# DSS_EDP0_V2A_CORE_VP_REGS_APB register map
Vendor: Texas Instruments
Registers are 32-bit, access not given, reset 0x0 unless marked. A register's access mark holds for its fields unless they carry their own. Offsets are as the file gives them; [hi:lo] are bit positions; lines under a group give offsets from that group; {n}, {i} and the like mark numbered series; 'fields as' and 'values as' point back to an identical list.

## DSS_EDP0_V2A_CORE_VP_REGS_APB (part 4 of 4)
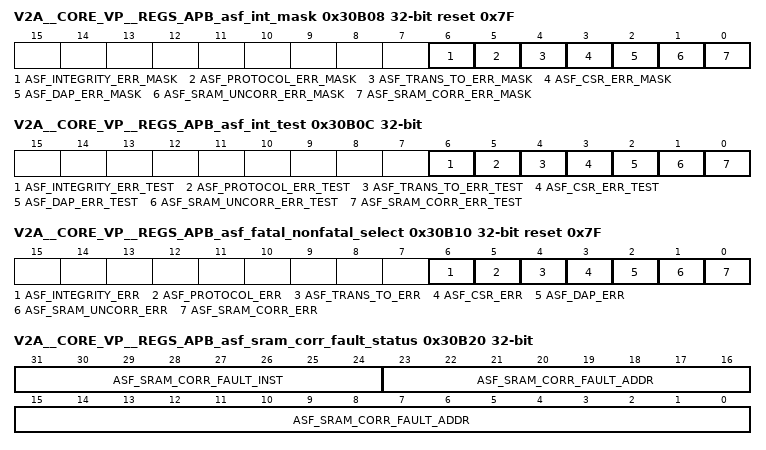
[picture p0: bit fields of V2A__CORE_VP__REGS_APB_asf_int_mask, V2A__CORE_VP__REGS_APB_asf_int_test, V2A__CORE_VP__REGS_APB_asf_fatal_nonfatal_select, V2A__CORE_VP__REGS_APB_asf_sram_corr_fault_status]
0x30B08 V2A__CORE_VP__REGS_APB_asf_int_mask reset 0x7F — The ASF interrupt mask register indicating which interrupt bits in the ASF interrupt status register are masked. All bits are set at reset. Clear the individual bit to enable the corresponding interrupt.
  [6] ASF_INTEGRITY_ERR_MASK rw — Mask bit for Integrity error interrupt, 0 is active, 1 is not active. Interrupt from source which mask is 0 is permitted, otherwise interrupt is not permitted
  [5] ASF_PROTOCOL_ERR_MASK rw — Mask bit for Protocol error interrupt, 0 is active, 1 is not active.Interrupt from source which mask is 0 is permitted, otherwise interrupt is not permitted
  [4] ASF_TRANS_TO_ERR_MASK rw — Mask bit for Transaction timeouts error interrupt, 0 is active, 1 is not active. Interrupt from source which mask is 0 is permitted, otherwise interrupt is not permitted
  [3] ASF_CSR_ERR_MASK rw — Mask bit for Configuration and status registers error interrupt, 0 is active, 1 is not active. Interrupt from source which mask is 0 is permitted, otherwise interrupt is not permitted
  [2] ASF_DAP_ERR_MASK rw — Mask bit for Data and address paths parity error interrupt, 0 is active, 1 is not active. Interrupt from source which mask is 0 is permitted, otherwise interrupt is not permitted
  [1] ASF_SRAM_UNCORR_ERR_MASK rw — Mask bit for SRAM uncorrectable error interrupt, 0 is active, 1 is not active. Interrupt from source which mask is 0 is permitted, otherwise interrupt is not permitted
  [0] ASF_SRAM_CORR_ERR_MASK rw — Mask bit for SRAM correctable error interrupt, 0 is active, 1 is not active. Interrupt from source which mask is 0 is permitted, otherwise interrupt is not permitted
0x30B0C V2A__CORE_VP__REGS_APB_asf_int_test — The ASF interrupt test register emulate hardware even. Write one to individual bit to trigger single event in (masked and raw) status registers according to mask and will generate interrupt accordingly.
  [6] ASF_INTEGRITY_ERR_TEST rw — Test bit for Integrity error interrupt,1 is active, 0 is not active
  [5] ASF_PROTOCOL_ERR_TEST rw — Test bit for Protocol error interrupt,1 is active, 0 is not active
  [4] ASF_TRANS_TO_ERR_TEST rw — Test bit for Transaction timeouts error interrupt,1 is active, 0 is not active
  [3] ASF_CSR_ERR_TEST rw — Test bit for Configuration and status registers error interrupt,1 is active, 0 is not active
  [2] ASF_DAP_ERR_TEST rw — Test bit for Data and address paths parity error interrupt,1 is active, 0 is not active
  [1] ASF_SRAM_UNCORR_ERR_TEST rw — Test bit for SRAM uncorrectable error interrupt,1 is active, 0 is not active
  [0] ASF_SRAM_CORR_ERR_TEST rw — Test bit for SRAM correctable error interrupt,1 is active, 0 is not active
0x30B10 V2A__CORE_VP__REGS_APB_asf_fatal_nonfatal_select reset 0x7F — The fatal or non-fatal interrupt register selects whether a fatal (asf_int_fatal) or non-fatal (asf_int_nonfatal) interrupt is triggered. If the bit of the event will be set to one then fatal interrupt (asf_int_fatal) will be triggered. Otherwise the non-fatal interrupt (asf_int_nonfatal) will be triggered.
  [6] ASF_INTEGRITY_ERR rw — Enable Integrity error interrupt as fatal,1 is fatal interrupt, 0 is non-fatal
  [5] ASF_PROTOCOL_ERR rw — Enable Protocol error interrupt as fatal,1 is fatal interrupt, 0 is non-fatal
  [4] ASF_TRANS_TO_ERR rw — Enable Transaction timeouts error interrupt as fatal,1 is fatal interrupt, 0 is non-fatal
  [3] ASF_CSR_ERR rw — Enable Configuration and status registers error interrupt as fatal,1 is fatal interrupt, 0 is non-fatal
  [2] ASF_DAP_ERR rw — Enable Data and address paths parity error interrupt as fatal,1 is fatal interrupt, 0 is non-fatal
  [1] ASF_SRAM_UNCORR_ERR rw — Enable SRAM uncorrectable error interrupt as fatal,1 is fatal interrupt, 0 is non-fatal
  [0] ASF_SRAM_CORR_ERR rw — Enable SRAM correctable error interrupt as fatal,1 is fatal interrupt, 0 is non-fatal
0x30B20 V2A__CORE_VP__REGS_APB_asf_sram_corr_fault_status ro — Status register for SRAM correctable fault. These fields are updated whenever asf_sram_corr_fault input is active.
  [31:24] ASF_SRAM_CORR_FAULT_INST — Last SRAM instance that generated fault
  [23:0] ASF_SRAM_CORR_FAULT_ADDR — Last SRAM address that generated fault
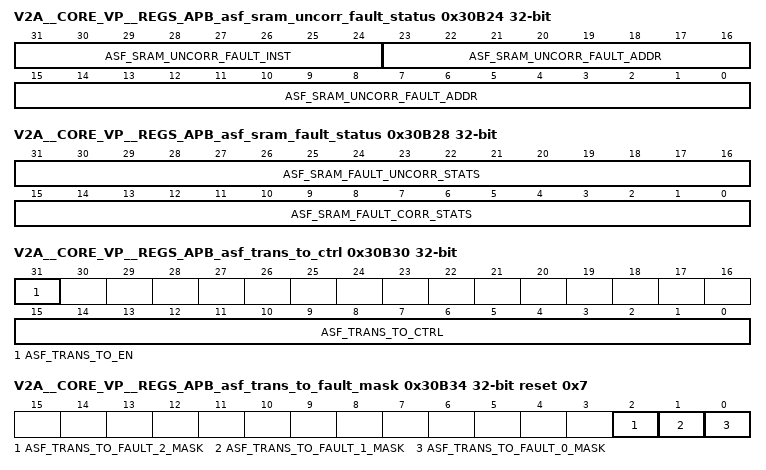
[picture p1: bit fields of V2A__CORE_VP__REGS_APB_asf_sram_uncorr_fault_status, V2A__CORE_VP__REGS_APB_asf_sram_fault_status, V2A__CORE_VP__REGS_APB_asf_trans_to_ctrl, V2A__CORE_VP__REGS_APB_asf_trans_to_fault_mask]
0x30B24 V2A__CORE_VP__REGS_APB_asf_sram_uncorr_fault_status ro — Status register for SRAM uncorrectable fault. These fields are updated whenever asf_sram_uncorr_fault input is active.
  [31:24] ASF_SRAM_UNCORR_FAULT_INST — Last SRAM instance that generated fault
  [23:0] ASF_SRAM_UNCORR_FAULT_ADDR — Last SRAM address that generated fault
0x30B28 V2A__CORE_VP__REGS_APB_asf_sram_fault_status rw — Statistics register for SRAM faults. Note that this register clears when software writes to any field.
  [31:16] ASF_SRAM_FAULT_UNCORR_STATS — Count of number of uncorrectable errors if implemented. Count value will saturate at 0xffff
  [15:0] ASF_SRAM_FAULT_CORR_STATS — Count of number of correctable errors if implemented. Count value will saturate at 0xffff
0x30B30 V2A__CORE_VP__REGS_APB_asf_trans_to_ctrl — Control register to configure the ASF transaction timeout monitors.
  [31] ASF_TRANS_TO_EN rw — Enable transaction timeout monitoring,1 is active,0 is not active
  [15:0] ASF_TRANS_TO_CTRL rw — Timer value to use for transaction timeout monitor
0x30B34 V2A__CORE_VP__REGS_APB_asf_trans_to_fault_mask reset 0x7 — Control register to mask out ASF transaction timeout faults from triggering interrupts. On reset, all bits are set to mask out all sources. Clear the corresponding bit to enable the interrupt source. The width of this field is parameterisable and the bit definitions are implementation specific.
  [2] ASF_TRANS_TO_FAULT_2_MASK rw — Mask bit for SAPB interface for transaction timeout fault,0 is active, 1 is not active.Interrupt from source which mask is 0 is permitted, otherwise interrupt is not permitted
  [1] ASF_TRANS_TO_FAULT_1_MASK rw — Mask bit for APB interface for transaction timeout fault,0 is active, 1 is not active.Interrupt from source which mask is 0 is permitted, otherwise interrupt is not permitted
  [0] ASF_TRANS_TO_FAULT_0_MASK rw — Mask bit for Xtensa watchdog error for transaction timeout fault,0 is active, 1 is not active.Interrupt from source which mask is 0 is permitted, otherwise interrupt is not permitted
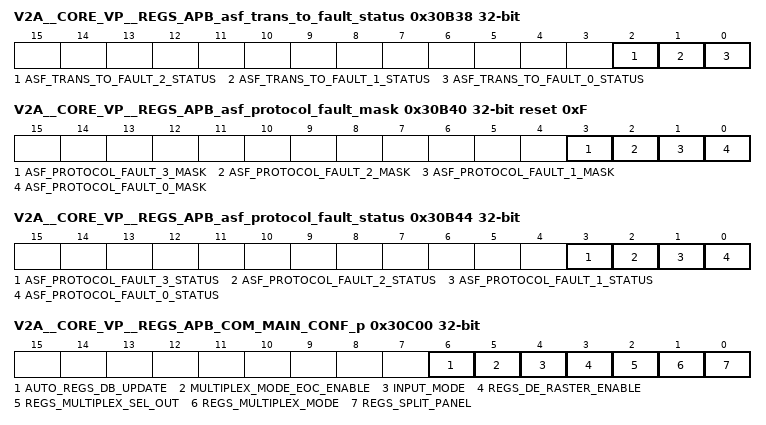
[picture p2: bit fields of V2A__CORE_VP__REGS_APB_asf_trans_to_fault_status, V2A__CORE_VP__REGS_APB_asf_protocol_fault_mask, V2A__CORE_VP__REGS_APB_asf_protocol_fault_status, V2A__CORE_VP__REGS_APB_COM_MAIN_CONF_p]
0x30B38 V2A__CORE_VP__REGS_APB_asf_trans_to_fault_status — Status register for transaction timeouts fault. If a fault occurs the revelant status bit will be set to 1. Each bit can be cleared by software writing 1 to each bit.
  [2] ASF_TRANS_TO_FAULT_2_STATUS rw — Status bits for SAPB interface for transaction timeout fault,1 is active, 0 is not active
  [1] ASF_TRANS_TO_FAULT_1_STATUS rw — Status bits for APB interface for transaction timeout fault,1 is active, 0 is not active
  [0] ASF_TRANS_TO_FAULT_0_STATUS rw — Status bits for Xtensa watchdog error for transaction timeout fault,1 is active, 0 is not active
0x30B40 V2A__CORE_VP__REGS_APB_asf_protocol_fault_mask reset 0xF — Control register to mask out ASF Protocol faults from triggering interrupts. On reset, all bits are set to mask out all sources. Clear the corresponding bit to enable the interrupt source. The width of this field is parameterisable and the bit definitions are implementation specific.
  [3] ASF_PROTOCOL_FAULT_3_MASK rw — Mask bit for FEC FSM fault. When 0 interrupt is enabled.
  [2] ASF_PROTOCOL_FAULT_2_MASK rw — Mask bit for 8b10b Encoding fault from FEC module. When 0 interrupt is enabled.
  [1] ASF_PROTOCOL_FAULT_1_MASK rw — Mask bit for Party Encoding fault from FEC module. When 0 interrupt is enabled.
  [0] ASF_PROTOCOL_FAULT_0_MASK rw — Mask bit for Parity Generation fault from FEC module. When 0 interrupt is enabled.
0x30B44 V2A__CORE_VP__REGS_APB_asf_protocol_fault_status — Status register for protocol faults. If a fault occurs the revelant status bit will be set to 1. Each bit can be cleared by software writing 1 to each bit
  [3] ASF_PROTOCOL_FAULT_3_STATUS rw — FEC symbol injection fault. Active HIGH. Asserten when FEC FSM is in unexpected state.
  [2] ASF_PROTOCOL_FAULT_2_STATUS rw — 8b10b Encoding fault in FEC module. Active HIGH. Asserted when fault in 8b10b encoding is detected.
  [1] ASF_PROTOCOL_FAULT_1_STATUS rw — Party Encoding fault in FEC module. Active HIGH. Asserted when fault in RS parity encoding is detected.
  [0] ASF_PROTOCOL_FAULT_0_STATUS rw — Parity Generation fault in FEC module. Active HIGH. Asserted when fault in RS parity generation is detected.
0x30C00 V2A__CORE_VP__REGS_APB_COM_MAIN_CONF_p — Encoder common configuration values
  [6] AUTO_REGS_DB_UPDATE rw — Active-High to enable auto update double buffer regs on vsync falling edge. Only available when input_mode=1 [DPI mode]
  [5] MULTIPLEX_MODE_EOC_ENABLE rw — When split_panel and multiplex_mode are set, indicates that multiplexer output separated chunks [inserts zeros on partial words at each end of chunk] and signal end of chunks. Active high
  [4] INPUT_MODE rw — Video input interface mode: 0: Native 1: DPI. Input mode set to DPI automatically enable the internal Auto Start Of Frame
  [3] REGS_DE_RASTER_ENABLE rw — Indicates if the De-Rasterization Buffer is used or bypassed: '1' Active '0' Bypassed
  [2] REGS_MULTIPLEX_SEL_OUT rw — When split_panel and multiplex_mode are set, indicates to which output the multiplexed stream is sent: '0': enc0_data_out '1': enc1_data_out
  [1] REGS_MULTIPLEX_MODE rw — Active-High, indicates that both encoders are used to produce a multiplex stream on a single Transport link. When set, split_panel must also be set.
  [0] REGS_SPLIT_PANEL rw — Active-High, indicates that both encoders are used in parallel for one video stream [L and R split]. When set, the effective width of each encoder is halved [as each encoder is operating on half of the encx_picture_width]. In addition, the ICH is cleared at the end of each line.
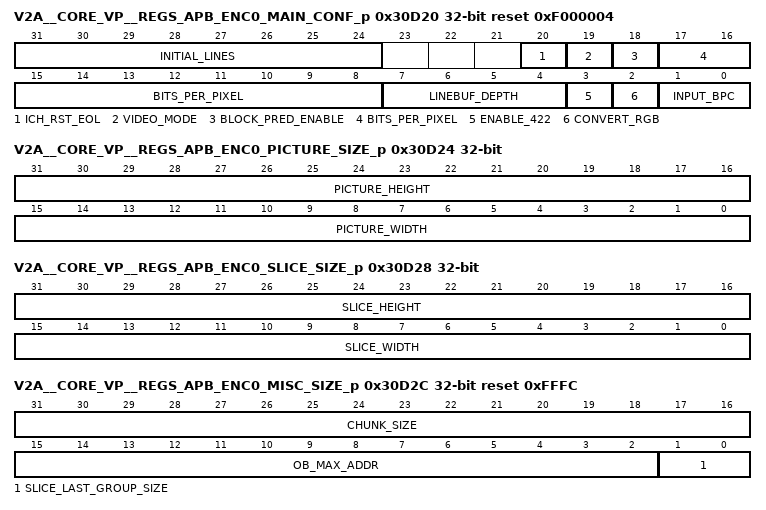
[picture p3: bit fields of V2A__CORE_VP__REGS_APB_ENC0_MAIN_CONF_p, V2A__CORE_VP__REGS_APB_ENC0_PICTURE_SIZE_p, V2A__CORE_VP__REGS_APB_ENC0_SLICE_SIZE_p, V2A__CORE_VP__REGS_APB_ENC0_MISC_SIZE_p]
0x30D20 V2A__CORE_VP__REGS_APB_ENC0_MAIN_CONF_p reset 0xF000004 — Encoder Main Configuration values
  [31:24] INITIAL_LINES rw — Number of lines to wait before initiating transport in Command Mode.
  [20] ICH_RST_EOL rw — Forces the ICH to reset at EOL [when not in split mode].
  [19] VIDEO_MODE rw — MIPI Video/Command mode: '0' Command mode '1' Video mode
  [18] BLOCK_PRED_ENABLE rw — Active-High input Block Prediction Enable
  [17:8] BITS_PER_PIXEL rw — Target bits per pixel. The value is in 6.4 format [4 LSBs for fractional part, they should be 0000]
  [7:4] LINEBUF_DEPTH rw — Depth of the line buffer used by the decoder [i.e., the number of bits stored for each component of the pixels on the previous line]
  [3] ENABLE_422 rw — Active-High input to indicate the data_in pixels are 4:2:2 sub-sampled. This input is valid only when convert_rgb is low. NOT SUPPORTED, MUST BE SET TO '0'
  [2] CONVERT_RGB rw — Active-High input to indicate the data_in pixels are RGB. When set to low input, it is YUV and does not require conversion.
  [1:0] INPUT_BPC rw — Indicates the current input pixel stream bits per component: 00: input is 8 bits/component 01: input is 10 bits/component
0x30D24 V2A__CORE_VP__REGS_APB_ENC0_PICTURE_SIZE_p rw — Encoder Picture configuration
  [31:16] PICTURE_HEIGHT, [15:0] PICTURE_WIDTH
0x30D28 V2A__CORE_VP__REGS_APB_ENC0_SLICE_SIZE_p rw — Encoder Slice(s) configuration
  [31:16] SLICE_HEIGHT, [15:0] SLICE_WIDTH
0x30D2C V2A__CORE_VP__REGS_APB_ENC0_MISC_SIZE_p rw reset 0xFFFC — Encoder Group, Output Buffer(s), and Transport Chunk Size
  [31:16] CHUNK_SIZE — Chunk size in bytes
  [15:2] OB_MAX_ADDR — Output Buffer[s] max pointer address[es]
  [1:0] SLICE_LAST_GROUP_SIZE — Size of last group of the slice line [0-based]: 0 = 1 pixel, 1 = 2 pixels, 2 = 3 pixels [slice_width + 2] % 3
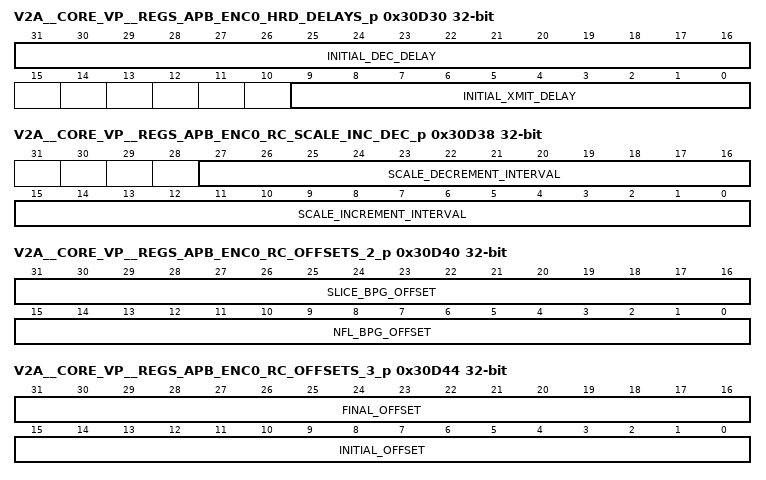
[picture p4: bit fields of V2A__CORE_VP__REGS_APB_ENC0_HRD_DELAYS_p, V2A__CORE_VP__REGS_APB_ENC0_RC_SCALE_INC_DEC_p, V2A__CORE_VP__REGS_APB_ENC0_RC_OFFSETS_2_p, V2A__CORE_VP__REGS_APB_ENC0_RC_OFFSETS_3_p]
0x30D30 V2A__CORE_VP__REGS_APB_ENC0_HRD_DELAYS_p — Hypothetical Reference Decoder delays
  [31:16] INITIAL_DEC_DELAY rw — Initial Decoder delay
  [9:0] INITIAL_XMIT_DELAY rw — Initial Decoder Transmit delay
0x30D34 V2A__CORE_VP__REGS_APB_ENC0_RC_SCALE_p — RC Calculate Buffer Fullness and Offset, Scale value
  [5:0] INITIAL_SCALE_VALUE rw — Three fractional bits
0x30D38 V2A__CORE_VP__REGS_APB_ENC0_RC_SCALE_INC_DEC_p — RC Calculate Buffer Fullness and Offset, Increment and Decrement Scale values
  [27:16] SCALE_DECREMENT_INTERVAL rw — RC scale decrement value
  [15:0] SCALE_INCREMENT_INTERVAL rw — RC scale increment value
0x30D3C V2A__CORE_VP__REGS_APB_ENC0_RC_OFFSETS_1_p — RC Calculate Buffer Fullness and Offset, Various Offset control values 1
  [4:0] FIRST_LINE_BPG_OFFSET rw — First Line
0x30D40 V2A__CORE_VP__REGS_APB_ENC0_RC_OFFSETS_2_p rw — RC Calculate Buffer Fullness and Offset, Various Offset control values 2
  [31:16] SLICE_BPG_OFFSET — Extra budget per group [11 fractional bits]
  [15:0] NFL_BPG_OFFSET — Non First Line [11 fractional bits]
0x30D44 V2A__CORE_VP__REGS_APB_ENC0_RC_OFFSETS_3_p rw — RC Calculate Buffer Fullness and Offset, Various Offset control values 3
  [31:16] FINAL_OFFSET, [15:0] INITIAL_OFFSET
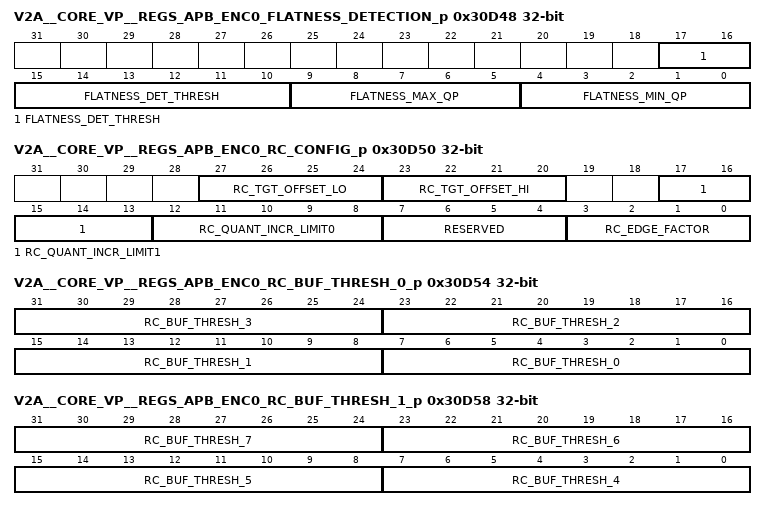
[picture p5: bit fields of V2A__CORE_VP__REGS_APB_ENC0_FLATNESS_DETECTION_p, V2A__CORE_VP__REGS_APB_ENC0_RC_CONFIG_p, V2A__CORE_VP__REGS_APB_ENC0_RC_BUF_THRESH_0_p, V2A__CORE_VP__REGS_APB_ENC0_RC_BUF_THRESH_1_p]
0x30D48 V2A__CORE_VP__REGS_APB_ENC0_FLATNESS_DETECTION_p — Flatness Signaling QP Override thresholds
  [17:10] FLATNESS_DET_THRESH rw — Flatness Detection Threshold, as defined in PPS table of the DSC specification
  [9:5] FLATNESS_MAX_QP rw — Maximum threshold
  [4:0] FLATNESS_MIN_QP rw — Minimum threshold
0x30D4C V2A__CORE_VP__REGS_APB_ENC0_RC_MODEL_SIZE_p — RC Model Size
  [15:0] RC_MODEL_SIZE rw
0x30D50 V2A__CORE_VP__REGS_APB_ENC0_RC_CONFIG_p — RC Model Various Config
  [27:24] RC_TGT_OFFSET_LO rw — RC Target offset low
  [23:20] RC_TGT_OFFSET_HI rw — RC Target offset high
  [17:13] RC_QUANT_INCR_LIMIT1 rw — RC quantization increment limit 1
  [12:8] RC_QUANT_INCR_LIMIT0 rw — RC quantization increment limit 0
  [7:4] RESERVED — RC Edge factor [1 fractional bit] (access N/A)
  [3:0] RC_EDGE_FACTOR rw — Reserved. Writes are ignored. 0x0 when read
0x30D54 V2A__CORE_VP__REGS_APB_ENC0_RC_BUF_THRESH_0_p rw — RC Model Buffer Thresholds 0
  [8n+7:8n] RC_BUF_THRESH_{n} (n=0..3) — 8 MSBs of the value. Values in configuration files are 14 bits but 6 LSBs are always 0
0x30D58 V2A__CORE_VP__REGS_APB_ENC0_RC_BUF_THRESH_1_p rw — RC Model Buffer Thresholds 1
  [8n-25:8n-32] RC_BUF_THRESH_{n} (n=4..7) — 8 MSBs of the value. Values in configuration files are 14 bits but 6 LSBs are always 0
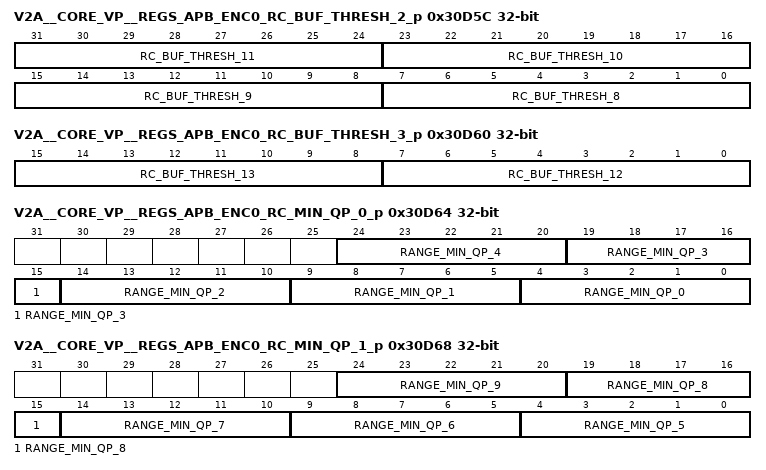
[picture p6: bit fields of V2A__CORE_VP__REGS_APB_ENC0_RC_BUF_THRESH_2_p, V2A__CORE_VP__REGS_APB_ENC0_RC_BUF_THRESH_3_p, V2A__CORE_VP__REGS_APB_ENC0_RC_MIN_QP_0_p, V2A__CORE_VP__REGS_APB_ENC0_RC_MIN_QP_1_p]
0x30D5C V2A__CORE_VP__REGS_APB_ENC0_RC_BUF_THRESH_2_p rw — RC Model Buffer Thresholds 2
  [8n-57:8n-64] RC_BUF_THRESH_{n} (n=8..11) — 8 MSBs of the value. Values in configuration files are 14 bits but 6 LSBs are always 0
0x30D60 V2A__CORE_VP__REGS_APB_ENC0_RC_BUF_THRESH_3_p — RC Model Buffer Thresholds 3
  [15:8] RC_BUF_THRESH_13 rw — 8 MSBs of the value. Values in configuration files are 14 bits but 6 LSBs are always 0
  [7:0] RC_BUF_THRESH_12 rw — 8 MSBs of the value. Values in configuration files are 14 bits but 6 LSBs are always 0
0x30D64 V2A__CORE_VP__REGS_APB_ENC0_RC_MIN_QP_0_p — RC Min QP 0
  [5n+4:5n] RANGE_MIN_QP_{n} rw (n=0..4) — As per DSC specification
0x30D68 V2A__CORE_VP__REGS_APB_ENC0_RC_MIN_QP_1_p — RC Min QP 1
  [5n-21:5n-25] RANGE_MIN_QP_{n} rw (n=5..9) — As per DSC specification
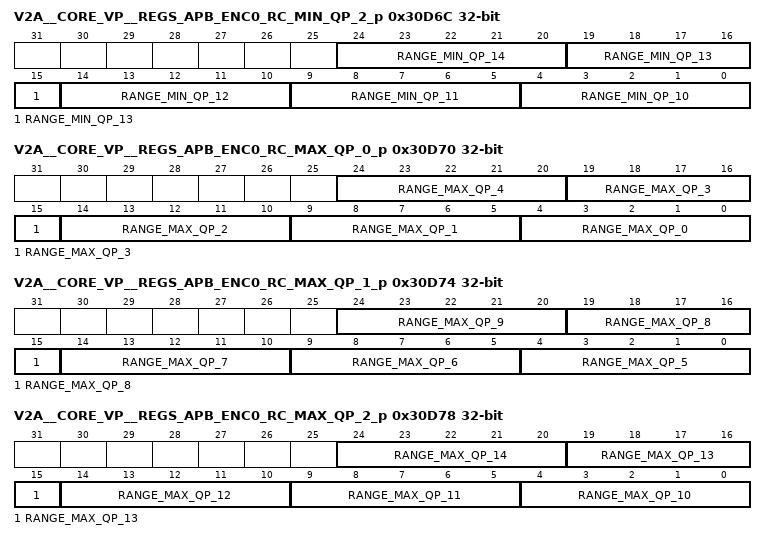
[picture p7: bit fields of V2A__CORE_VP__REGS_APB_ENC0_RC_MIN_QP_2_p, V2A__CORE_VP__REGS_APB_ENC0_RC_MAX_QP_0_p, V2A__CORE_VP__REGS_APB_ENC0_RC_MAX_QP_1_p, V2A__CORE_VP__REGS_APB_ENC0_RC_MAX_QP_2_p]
0x30D6C V2A__CORE_VP__REGS_APB_ENC0_RC_MIN_QP_2_p — RC Min QP 2
  [5n-46:5n-50] RANGE_MIN_QP_{n} rw (n=10..14) — As per DSC specification
0x30D70 V2A__CORE_VP__REGS_APB_ENC0_RC_MAX_QP_0_p — RC Max QP 0
  [5n+4:5n] RANGE_MAX_QP_{n} rw (n=0..4) — As per DSC specification
0x30D74 V2A__CORE_VP__REGS_APB_ENC0_RC_MAX_QP_1_p — RC Max QP 1
  [5n-21:5n-25] RANGE_MAX_QP_{n} rw (n=5..9) — As per DSC specification
0x30D78 V2A__CORE_VP__REGS_APB_ENC0_RC_MAX_QP_2_p — RC Max QP 2
  [5n-46:5n-50] RANGE_MAX_QP_{n} rw (n=10..14) — As per DSC specification
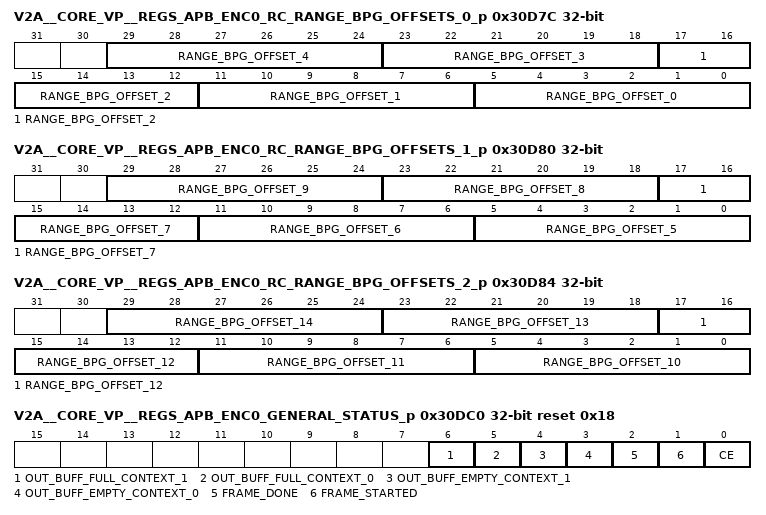
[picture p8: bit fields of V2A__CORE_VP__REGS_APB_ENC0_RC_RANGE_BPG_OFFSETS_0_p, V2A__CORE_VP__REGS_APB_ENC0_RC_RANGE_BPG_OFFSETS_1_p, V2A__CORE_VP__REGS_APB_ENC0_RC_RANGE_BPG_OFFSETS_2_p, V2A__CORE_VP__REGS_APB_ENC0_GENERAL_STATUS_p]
0x30D7C V2A__CORE_VP__REGS_APB_ENC0_RC_RANGE_BPG_OFFSETS_0_p — RC Range bpg Offsets 0
  [6n+5:6n] RANGE_BPG_OFFSET_{n} rw (n=0..4) — As per DSC specification
0x30D80 V2A__CORE_VP__REGS_APB_ENC0_RC_RANGE_BPG_OFFSETS_1_p — RC Range bpg Offsets 1
  [6n-25:6n-30] RANGE_BPG_OFFSET_{n} rw (n=5..9) — As per DSC specification
0x30D84 V2A__CORE_VP__REGS_APB_ENC0_RC_RANGE_BPG_OFFSETS_2_p — RC Range bpg Offsets 2
  [6n-55:6n-60] RANGE_BPG_OFFSET_{n} rw (n=10..14) — As per DSC specification
0x30D88 V2A__CORE_VP__REGS_APB_ENC0_DPI_CTRL_OUT_DELAY_p — Delay applied to DPI input control signals to generate DPI output control signals
  [15:0] DPI_CTRL_OUT_DELAY rw — Delay in number of encx clock cycles. The delay should equal to InitialLines x Htotal[clk] where Htotal is the upstream source timing controller total line time [in clock cycles, not in pixels] including the horizontal blanking [Htotal[clk] = Hactive[clk] + Hblank[clk]]When in split panel mode, the Hactive[clk] is expected to be picture_width divided by 2
0x30DC0 V2A__CORE_VP__REGS_APB_ENC0_GENERAL_STATUS_p reset 0x18 — General Encoder Status
  [6] OUT_BUFF_FULL_CONTEXT_1 ro — Output buffer 1 [soft slice 1] is full.For Debug purposes only.
  [5] OUT_BUFF_FULL_CONTEXT_0 ro — Output buffer 0 [soft slice 0] is full.For Debug purposes only.
  [4] OUT_BUFF_EMPTY_CONTEXT_1 ro — Output buffer 1 [soft slice 1] is empty.For Debug purposes only.
  [3] OUT_BUFF_EMPTY_CONTEXT_0 ro — Output buffer 0 [soft slice 0] is empty.For Debug purposes only.
  [2] FRAME_DONE ro — Encoder finished a frame
  [1] FRAME_STARTED ro — Encoder is currently processing a frame
  [0] CE ro — Flow control internal clock enable status.For Debug purposes only.
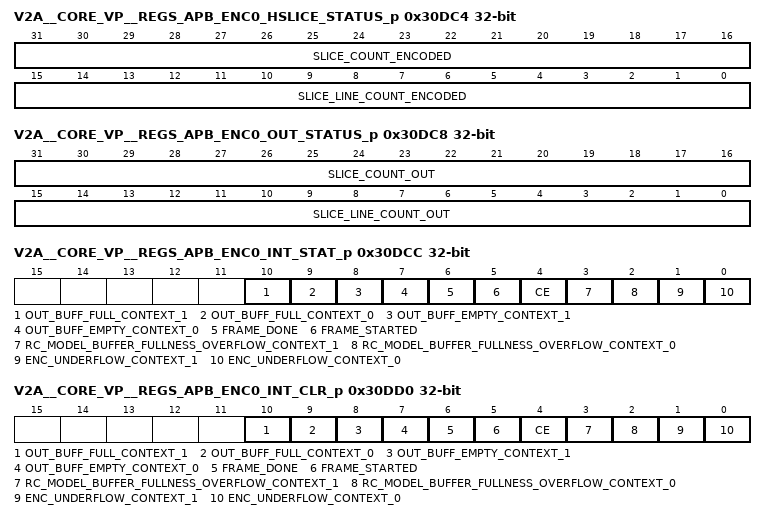
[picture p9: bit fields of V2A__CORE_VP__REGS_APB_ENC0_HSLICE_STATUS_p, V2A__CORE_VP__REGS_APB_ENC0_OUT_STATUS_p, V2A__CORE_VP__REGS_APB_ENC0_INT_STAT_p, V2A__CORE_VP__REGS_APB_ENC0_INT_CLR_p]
0x30DC4 V2A__CORE_VP__REGS_APB_ENC0_HSLICE_STATUS_p ro — Hard Slice Encoded Status
  [31:16] SLICE_COUNT_ENCODED — Actual slice number of current frame being processed at VLC encoder.Not re-synchronized in register clock domain. For Debug purposes only.
  [15:0] SLICE_LINE_COUNT_ENCODED — Actual line number of current slice being processed at VLC encoder.Not re-synchronized in register clock domain. For Debug purposes only.
0x30DC8 V2A__CORE_VP__REGS_APB_ENC0_OUT_STATUS_p ro — Outputted Slice Status
  [31:16] SLICE_COUNT_OUT — Actual slice number of current frame being read at output interface.Not re-synchronized in register clock domain. For Debug purposes only.
  [15:0] SLICE_LINE_COUNT_OUT — Actual line number of current slice being read at output interface.Not re-synchronized in register clock domain. For Debug purposes only.
0x30DCC V2A__CORE_VP__REGS_APB_ENC0_INT_STAT_p — Encoder Interrupt Status
  [10] OUT_BUFF_FULL_CONTEXT_1 ro — Output buffer 1 [soft slice 1] became full
  [9] OUT_BUFF_FULL_CONTEXT_0 ro — Output buffer 0 [soft slice 0] became full
  [8] OUT_BUFF_EMPTY_CONTEXT_1 ro — Output buffer 1 [soft slice 1] became empty
  [7] OUT_BUFF_EMPTY_CONTEXT_0 ro — Output buffer 0 [soft slice 0] became empty
  [6] FRAME_DONE ro — Encoder finished a frame
  [5] FRAME_STARTED ro — Encoder is started to process a frame
  [4] CE ro — Flow control internal clock enable becomes high
  [3] RC_MODEL_BUFFER_FULLNESS_OVERFLOW_CONTEXT_1 ro — rc_model_buffer 1 [soft slice 1] overflow
  [2] RC_MODEL_BUFFER_FULLNESS_OVERFLOW_CONTEXT_0 ro — rc_model_buffer 0 [soft slice 0] overflow
  [1] ENC_UNDERFLOW_CONTEXT_1 ro — output buffer 1 [soft slice 1] underflow
  [0] ENC_UNDERFLOW_CONTEXT_0 ro — output buffer 0 [soft slice 0] underflow
0x30DD0 V2A__CORE_VP__REGS_APB_ENC0_INT_CLR_p — Encoder Interrupt Clear. Setting any one of these bits, clears the corresponding ENC_INT_STAT bits. This register is self-clearing after 8 regs_pclk cycles.
  [10] OUT_BUFF_FULL_CONTEXT_1 rw — Output buffer 1 [soft slice 1] became full
  [9] OUT_BUFF_FULL_CONTEXT_0 rw — Output buffer 0 [soft slice 0] became full
  [8] OUT_BUFF_EMPTY_CONTEXT_1 rw — Output buffer 1 [soft slice 1] became empty
  [7] OUT_BUFF_EMPTY_CONTEXT_0 rw — Output buffer 0 [soft slice 0] became empty
  [6] FRAME_DONE rw — Encoder finished a frame
  [5] FRAME_STARTED rw — Encoder is started to process a frame
  [4] CE rw — Flow control internal clock enable
  [3] RC_MODEL_BUFFER_FULLNESS_OVERFLOW_CONTEXT_1 rw — rc model buffer 1 overflow
  [2] RC_MODEL_BUFFER_FULLNESS_OVERFLOW_CONTEXT_0 rw — rc model buffer 0 overflow
  [1] ENC_UNDERFLOW_CONTEXT_1 rw — output buffer 1 underflow
  [0] ENC_UNDERFLOW_CONTEXT_0 rw — output buffer 0 underflow
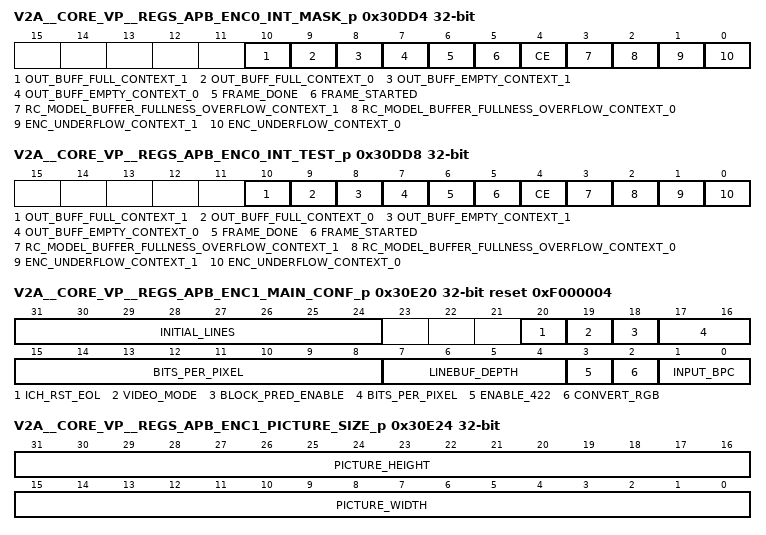
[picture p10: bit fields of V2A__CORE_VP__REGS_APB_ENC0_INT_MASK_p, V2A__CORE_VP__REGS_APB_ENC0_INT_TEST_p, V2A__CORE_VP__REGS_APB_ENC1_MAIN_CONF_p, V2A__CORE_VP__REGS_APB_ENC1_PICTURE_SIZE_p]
0x30DD4 V2A__CORE_VP__REGS_APB_ENC0_INT_MASK_p — Encoder Interrupt Mask. Any bit set to 1'b1 is enabled to report an interrupt on the corresponding bit position
  [10] OUT_BUFF_FULL_CONTEXT_1 rw — Output buffer 1 [soft slice 1] became full
  [9] OUT_BUFF_FULL_CONTEXT_0 rw — Output buffer 0 [soft slice 0] became full
  [8] OUT_BUFF_EMPTY_CONTEXT_1 rw — Output buffer 1 [soft slice 1] became empty
  [7] OUT_BUFF_EMPTY_CONTEXT_0 rw — Output buffer 0 [soft slice 0] became empty
  [6] FRAME_DONE rw — Encoder finished a frame
  [5] FRAME_STARTED rw — Encoder is started to process a frame
  [4] CE rw — Flow control internal clock enable
  [3] RC_MODEL_BUFFER_FULLNESS_OVERFLOW_CONTEXT_1 rw — rc model buffer 1 overflow
  [2] RC_MODEL_BUFFER_FULLNESS_OVERFLOW_CONTEXT_0 rw — rc model buffer 0 overflow
  [1] ENC_UNDERFLOW_CONTEXT_1 rw — enc underflow 1 underflow
  [0] ENC_UNDERFLOW_CONTEXT_0 rw — enc underflow 0 underflow
0x30DD8 V2A__CORE_VP__REGS_APB_ENC0_INT_TEST_p — Encoder Interrupt Test. Setting any one of these bits to 0x0 and then to 0x1 simulate a hardware event and generate an interrupt if the corresponding ENCx_INT_MASK bit is set.
  [10] OUT_BUFF_FULL_CONTEXT_1 rw — Output buffer 1 [soft slice 1] became full test
  [9] OUT_BUFF_FULL_CONTEXT_0 rw — Output buffer 0 [soft slice 0] became full test
  [8] OUT_BUFF_EMPTY_CONTEXT_1 rw — Output buffer 1 [soft slice 1] became empty test
  [7] OUT_BUFF_EMPTY_CONTEXT_0 rw — Output buffer 0 [soft slice 0] became empty test
  [6] FRAME_DONE rw — Encoder finished a frame test
  [5] FRAME_STARTED rw — Encoder is started to process a frame test
  [4] CE rw — Flow control internal clock enable test
  [3] RC_MODEL_BUFFER_FULLNESS_OVERFLOW_CONTEXT_1 rw — rc model buffer 1 overflow test
  [2] RC_MODEL_BUFFER_FULLNESS_OVERFLOW_CONTEXT_0 rw — rc model buffer 0 overflow test
  [1] ENC_UNDERFLOW_CONTEXT_1 rw — enc underflow 1 underflow test
  [0] ENC_UNDERFLOW_CONTEXT_0 rw — enc underflow 0 underflow test
0x30E20 V2A__CORE_VP__REGS_APB_ENC1_MAIN_CONF_p reset 0xF000004 — Encoder Main Configuration values test
  fields as V2A__CORE_VP__REGS_APB_ENC0_MAIN_CONF_p
0x30E24 V2A__CORE_VP__REGS_APB_ENC1_PICTURE_SIZE_p rw — Encoder Picture configuration
  [31:16] PICTURE_HEIGHT, [15:0] PICTURE_WIDTH
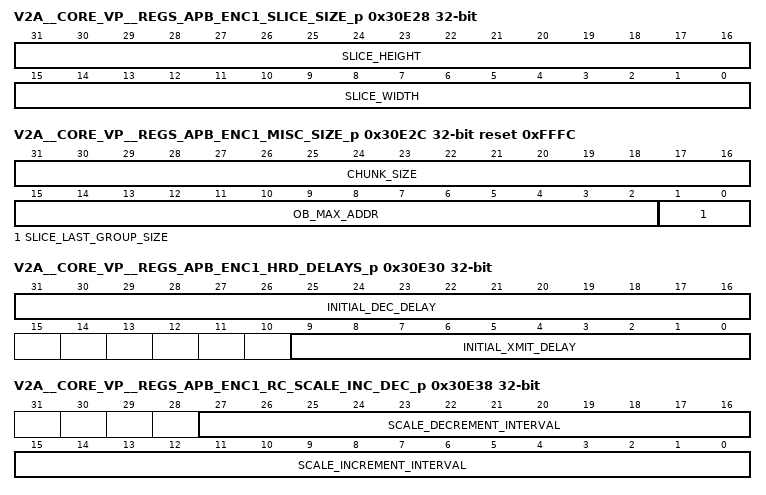
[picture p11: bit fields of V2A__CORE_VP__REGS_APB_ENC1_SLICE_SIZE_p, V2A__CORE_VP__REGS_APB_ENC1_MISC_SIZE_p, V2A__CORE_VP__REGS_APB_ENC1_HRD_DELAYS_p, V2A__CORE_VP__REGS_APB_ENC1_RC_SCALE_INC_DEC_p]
0x30E28 V2A__CORE_VP__REGS_APB_ENC1_SLICE_SIZE_p rw — Encoder Slice(s) configuration
  [31:16] SLICE_HEIGHT, [15:0] SLICE_WIDTH
0x30E2C V2A__CORE_VP__REGS_APB_ENC1_MISC_SIZE_p rw reset 0xFFFC — Encoder Group, Output Buffer(s), and Transport Chunk Size
  fields as V2A__CORE_VP__REGS_APB_ENC0_MISC_SIZE_p
0x30E30 V2A__CORE_VP__REGS_APB_ENC1_HRD_DELAYS_p — Hypothetical Reference Decoder delays
  fields as V2A__CORE_VP__REGS_APB_ENC0_HRD_DELAYS_p
0x30E34 V2A__CORE_VP__REGS_APB_ENC1_RC_SCALE_p — RC Calculate Buffer Fullness and Offset, Scale value
  [5:0] INITIAL_SCALE_VALUE rw — Three fractional bits
0x30E38 V2A__CORE_VP__REGS_APB_ENC1_RC_SCALE_INC_DEC_p — RC Calculate Buffer Fullness and Offset, Increment and Decrement Scale values
  fields as V2A__CORE_VP__REGS_APB_ENC0_RC_SCALE_INC_DEC_p
0x30E3C V2A__CORE_VP__REGS_APB_ENC1_RC_OFFSETS_1_p — RC Calculate Buffer Fullness and Offset, Various Offset control values 1
  [4:0] FIRST_LINE_BPG_OFFSET rw — First Line
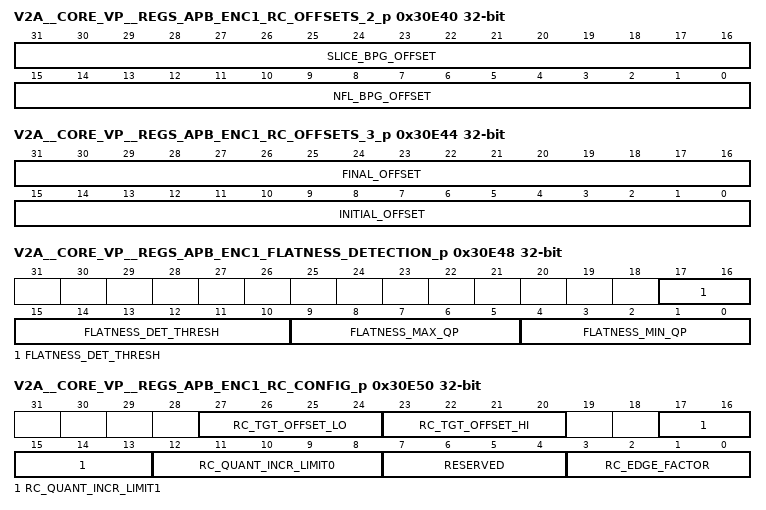
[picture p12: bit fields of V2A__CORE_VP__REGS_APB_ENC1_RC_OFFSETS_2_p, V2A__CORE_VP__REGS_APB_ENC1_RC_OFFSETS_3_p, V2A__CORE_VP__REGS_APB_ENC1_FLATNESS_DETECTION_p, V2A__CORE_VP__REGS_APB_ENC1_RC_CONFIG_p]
0x30E40 V2A__CORE_VP__REGS_APB_ENC1_RC_OFFSETS_2_p rw — RC Calculate Buffer Fullness and Offset, Various Offset control values 2
  fields as V2A__CORE_VP__REGS_APB_ENC0_RC_OFFSETS_2_p
0x30E44 V2A__CORE_VP__REGS_APB_ENC1_RC_OFFSETS_3_p rw — RC Calculate Buffer Fullness and Offset, Various Offset control values 3
  [31:16] FINAL_OFFSET, [15:0] INITIAL_OFFSET
0x30E48 V2A__CORE_VP__REGS_APB_ENC1_FLATNESS_DETECTION_p — Flatness Signaling QP Override thresholds
  fields as V2A__CORE_VP__REGS_APB_ENC0_FLATNESS_DETECTION_p
0x30E4C V2A__CORE_VP__REGS_APB_ENC1_RC_MODEL_SIZE_p — RC Model Size
  [15:0] RC_MODEL_SIZE rw
0x30E50 V2A__CORE_VP__REGS_APB_ENC1_RC_CONFIG_p — RC Model Various Config
  fields as V2A__CORE_VP__REGS_APB_ENC0_RC_CONFIG_p
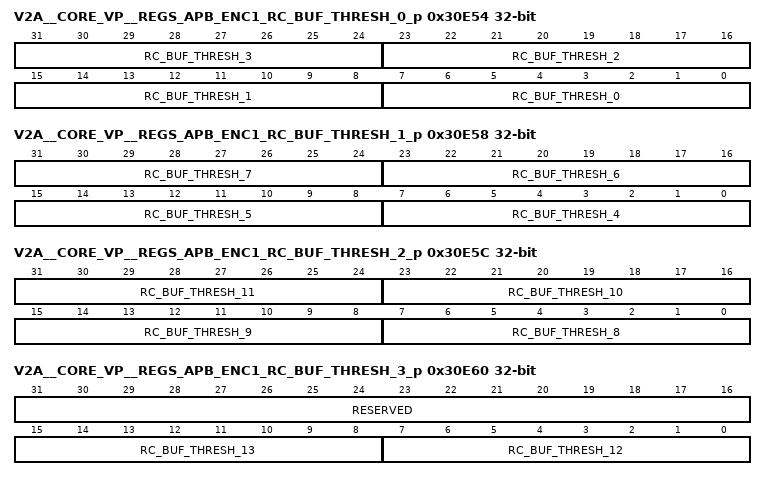
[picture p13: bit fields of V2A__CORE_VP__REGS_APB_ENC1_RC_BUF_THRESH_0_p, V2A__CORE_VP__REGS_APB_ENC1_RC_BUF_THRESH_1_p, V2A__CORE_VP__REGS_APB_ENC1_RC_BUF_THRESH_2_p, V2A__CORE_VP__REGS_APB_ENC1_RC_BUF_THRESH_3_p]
0x30E54 V2A__CORE_VP__REGS_APB_ENC1_RC_BUF_THRESH_0_p rw — RC Model Buffer Thresholds 0
  fields as V2A__CORE_VP__REGS_APB_ENC0_RC_BUF_THRESH_0_p
0x30E58 V2A__CORE_VP__REGS_APB_ENC1_RC_BUF_THRESH_1_p rw — RC Model Buffer Thresholds 1
  fields as V2A__CORE_VP__REGS_APB_ENC0_RC_BUF_THRESH_1_p
0x30E5C V2A__CORE_VP__REGS_APB_ENC1_RC_BUF_THRESH_2_p rw — RC Model Buffer Thresholds 2
  fields as V2A__CORE_VP__REGS_APB_ENC0_RC_BUF_THRESH_2_p
0x30E60 V2A__CORE_VP__REGS_APB_ENC1_RC_BUF_THRESH_3_p — RC Model Buffer Thresholds 3
  [31:16] RESERVED — 8 MSBs of the value. Values in configuration files are 14 bits but 6 LSBs are always 0 (access N/A)
  [15:8] RC_BUF_THRESH_13 rw — 8 MSBs of the value. Values in configuration files are 14 bits but 6 LSBs are always 0
  [7:0] RC_BUF_THRESH_12 rw — 8 MSBs of the value. Values in configuration files are 14 bits but 6 LSBs are always 0
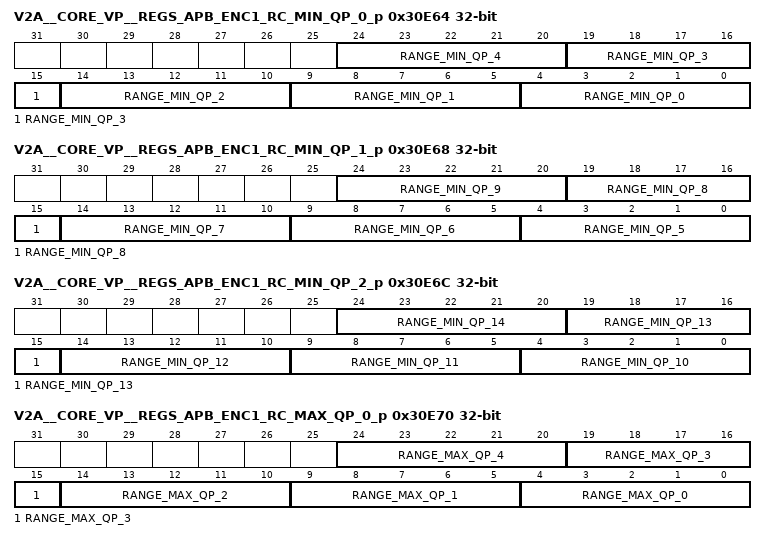
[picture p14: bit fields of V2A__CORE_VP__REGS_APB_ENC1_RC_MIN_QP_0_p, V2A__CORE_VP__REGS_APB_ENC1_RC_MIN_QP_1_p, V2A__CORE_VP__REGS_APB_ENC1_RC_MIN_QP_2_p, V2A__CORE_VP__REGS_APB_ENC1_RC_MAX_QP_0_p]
0x30E64 V2A__CORE_VP__REGS_APB_ENC1_RC_MIN_QP_0_p — RC Min QP 0
  [5n+4:5n] RANGE_MIN_QP_{n} rw (n=0..4) — As per DSC specification
0x30E68 V2A__CORE_VP__REGS_APB_ENC1_RC_MIN_QP_1_p — RC Min QP 1
  fields as V2A__CORE_VP__REGS_APB_ENC0_RC_MIN_QP_1_p
0x30E6C V2A__CORE_VP__REGS_APB_ENC1_RC_MIN_QP_2_p — RC Min QP 2
  fields as V2A__CORE_VP__REGS_APB_ENC0_RC_MIN_QP_2_p
0x30E70 V2A__CORE_VP__REGS_APB_ENC1_RC_MAX_QP_0_p — RC Max QP 0
  [5n+4:5n] RANGE_MAX_QP_{n} rw (n=0..4) — As per DSC specification
0x30E74 V2A__CORE_VP__REGS_APB_ENC1_RC_MAX_QP_1_p — RC Max QP 1
  fields as V2A__CORE_VP__REGS_APB_ENC0_RC_MAX_QP_1_p
0x30E78 V2A__CORE_VP__REGS_APB_ENC1_RC_MAX_QP_2_p — RC Max QP 2
  fields as V2A__CORE_VP__REGS_APB_ENC0_RC_MAX_QP_2_p
0x30E7C V2A__CORE_VP__REGS_APB_ENC1_RC_RANGE_BPG_OFFSETS_0_p — RC Range bpg Offsets 0
  fields as V2A__CORE_VP__REGS_APB_ENC0_RC_RANGE_BPG_OFFSETS_0_p
0x30E80 V2A__CORE_VP__REGS_APB_ENC1_RC_RANGE_BPG_OFFSETS_1_p — RC Range bpg Offsets 1
  fields as V2A__CORE_VP__REGS_APB_ENC0_RC_RANGE_BPG_OFFSETS_1_p
0x30E84 V2A__CORE_VP__REGS_APB_ENC1_RC_RANGE_BPG_OFFSETS_2_p — RC Range bpg Offsets 2
  fields as V2A__CORE_VP__REGS_APB_ENC0_RC_RANGE_BPG_OFFSETS_2_p
0x30E88 V2A__CORE_VP__REGS_APB_ENC1_DPI_CTRL_OUT_DELAY_p — Delay applied to DPI input control signals to generate DPI output control signals
  fields as V2A__CORE_VP__REGS_APB_ENC0_DPI_CTRL_OUT_DELAY_p
0x30EC0 V2A__CORE_VP__REGS_APB_ENC1_GENERAL_STATUS_p reset 0x18 — General Encoder Status
  fields as V2A__CORE_VP__REGS_APB_ENC0_GENERAL_STATUS_p
0x30EC4 V2A__CORE_VP__REGS_APB_ENC1_HSLICE_STATUS_p ro — Hard Slice Encoded Status
  fields as V2A__CORE_VP__REGS_APB_ENC0_HSLICE_STATUS_p
0x30EC8 V2A__CORE_VP__REGS_APB_ENC1_OUT_STATUS_p ro — Outputted Slice Status
  fields as V2A__CORE_VP__REGS_APB_ENC0_OUT_STATUS_p
0x30ECC V2A__CORE_VP__REGS_APB_ENC1_INT_STAT_p — Encoder Interrupt Status
  [10] OUT_BUFF_FULL_CONTEXT_1 ro — Output buffer 1 [soft slice 1] became full
  [9] OUT_BUFF_FULL_CONTEXT_0 ro — Output buffer 0 [soft slice 0] became full
  [8] OUT_BUFF_EMPTY_CONTEXT_1 ro — Output buffer 1 [soft slice 1] became empty
  [7] OUT_BUFF_EMPTY_CONTEXT_0 ro — Output buffer 0 [soft slice 0] became empty
  [6] FRAME_DONE ro — Encoder finished a frame
  [5] FRAME_STARTED ro — Encoder is started to process a frame
  [4] CE ro — Flow control internal clock enable becomes high
  [3] RC_MODEL_BUFFER_FULLNESS_OVERFLOW_CONTEXT_1 ro — output buffer 1 [soft slice 1] underflow
  [2] RC_MODEL_BUFFER_FULLNESS_OVERFLOW_CONTEXT_0 ro — output buffer 0 [soft slice 0] underflow
  [1] ENC_UNDERFLOW_CONTEXT_1 ro — output buffer 1 [soft slice 1] underflow
  [0] ENC_UNDERFLOW_CONTEXT_0 ro — output buffer 0 [soft slice 0] underflow
0x30ED0 V2A__CORE_VP__REGS_APB_ENC1_INT_CLR_p — Encoder Interrupt Clear. Setting any one of these bits, clears the corresponding ENC_INT_STAT bits. This register is self-clearing after 8 regs_pclk cycles.
  fields as V2A__CORE_VP__REGS_APB_ENC0_INT_CLR_p
0x30ED4 V2A__CORE_VP__REGS_APB_ENC1_INT_MASK_p — Encoder Interrupt Mask. Any bit set to 1'b1 is enabled to report an interrupt on the corresponding bit position
  fields as V2A__CORE_VP__REGS_APB_ENC0_INT_MASK_p
0x30ED8 V2A__CORE_VP__REGS_APB_ENC1_INT_TEST_p — Encoder Interrupt Test. Setting any one of these bits to 0x0 and then to 0x1 simulate a hardware event and generate an interrupt if the corresponding ENCx_INT_MASK bit is set.
  fields as V2A__CORE_VP__REGS_APB_ENC0_INT_TEST_p
0x30F00 V2A__CORE_VP__REGS_APB_ENC_ASF_INT_STAT_p — Encoder ASF Interrupt Status
  [8] ASF_CSR_ERR ro — Configuration and status registers uncorrectable error interrupt
  [7] ENC1_SELF_CHK_ERR ro — Hard Slice 1 Encoder self-check uncorrectable error interrupt
  [6] ENC1_OUT_CHK_ERR ro — Hard Slice 1 Encoder output checker uncorrectable error interrupt
  [5] ENC1_ASF_SRAM_UNCORR_ERR ro — Hard Slice 1 SRAM uncorrectable error interrupt
  [4] ENC1_ASF_SRAM_CORR_ERR ro — Hard Slice 1 SRAM correctable error interrupt
  [3] ENC0_SELF_CHK_ERR ro — Hard Slice 0 Encoder self-check uncorrectable error interrupt
  [2] ENC0_OUT_CHK_ERR ro — Hard Slice 0 Encoder output checker uncorrectable error interrupt
  [1] ENC0_ASF_SRAM_UNCORR_ERR rw — Hard Slice 0 SRAM uncorrectable error interrupt
  [0] ENC0_ASF_SRAM_CORR_ERR ro — Hard Slice 0 SRAM correctable error interrupt
0x30F04 V2A__CORE_VP__REGS_APB_ENC_ASF_INT_MASK_p — Encoder ASF Interrupt Mask. Any bit set to 1'b1 is enabled to report an interrupt on the corresponding bit position
  [8] ASF_CSR_ERR rw — Configuration and status registers uncorrectable error interrupt
  [7] ENC1_SELF_CHK_ERR rw — Hard Slice 1 Encoder self-check uncorrectable error interrupt
  [6] ENC1_OUT_CHK_ERR rw — Hard Slice 1 Encoder output checker uncorrectable error interrupt
  [5] ENC1_ASF_SRAM_UNCORR_ERR rw — Hard Slice 1 SRAM uncorrectable error interrupt
  [4] ENC1_ASF_SRAM_CORR_ERR rw — Hard Slice 1 SRAM correctable error interrupt
  [3] ENC0_SELF_CHK_ERR rw — Hard Slice 0 Encoder self-check uncorrectable error interrupt
  [2] ENC0_OUT_CHK_ERR rw — Hard Slice 0 Encoder output checker uncorrectable error interrupt
  [1] ENC0_ASF_SRAM_UNCORR_ERR rw — Hard Slice 0 SRAM uncorrectable error interrupt
  [0] ENC0_ASF_SRAM_CORR_ERR rw — Hard Slice 0 SRAM correctable error interrupt
0x30F08 V2A__CORE_VP__REGS_APB_ENC_ASF_INT_CLR_p — Encoder ASF Interrupt Clear. Setting any one of these bits, clears the corresponding ENC_ASF_INT_STAT bits
  fields as V2A__CORE_VP__REGS_APB_ENC_ASF_INT_MASK_p
0x30F0C V2A__CORE_VP__REGS_APB_ENC_ASF_INT_TEST_p — Encoder ASF Interrupt Test. Setting any one of these bits to 0x0 and then to 0x1 simulate a hardware event and generate an interrupt if the corresponding ENC_ASF_INT_MASK bit is set
  [8] ASF_CSR_ERR rw — Configuration and status registers uncorrectable error interrupt test
  [7] ENC1_SELF_CHK_ERR rw — Hard Slice 1 Encoder self-check uncorrectable error interrupt test
  [6] ENC1_OUT_CHK_ERR rw — Hard Slice 1 Encoder output checker uncorrectable error interrupt test
  [5] ENC1_ASF_SRAM_UNCORR_ERR rw — Hard Slice 1 SRAM uncorrectable error interrupt test
  [4] ENC1_ASF_SRAM_CORR_ERR rw — Hard Slice 1 SRAM correctable error interrupt test
  [3] ENC0_SELF_CHK_ERR rw — Hard Slice 0 Encoder self-check uncorrectable error interrupt test
  [2] ENC0_OUT_CHK_ERR rw — Hard Slice 0 Encoder output checker uncorrectable error interrupt test
  [1] ENC0_ASF_SRAM_UNCORR_ERR rw — Hard Slice 0 SRAM uncorrectable error interrupt test
  [0] ENC0_ASF_SRAM_CORR_ERR rw — Hard Slice 0 SRAM correctable error interrupt test
0x30F20 V2A__CORE_VP__REGS_APB_ENC0_ASF_SRAM_CORR_p — Hard Slice 0 Status register for SRAM uncorrectable fault
  [25:24] ASF_SRAM_CORR_FAULT_INST ro — Last SRAM instance that generated fault. In case of simultaneous faults, priority is given to the highest number below. 3: SSM_S 2: SSM_D 1: Output Buffer 0: Line Buffer
  [23:0] ASF_SRAM_CORR_FAULT_ADDR ro — Last SRAM address that generated fault
0x30F24 V2A__CORE_VP__REGS_APB_ENC0_ASF_SRAM_UNCORR_p — Hard Slice 0 Status register for SRAM uncorrectable fault
  [25:24] ASF_SRAM_UNCORR_FAULT_INST ro — Last SRAM instance that generated fault. In case of simultaneous faults, priority is given to the highest number below. 3: SSM_S 2: SSM_D 1: Output Buffer 0: Line Buffer
  [23:0] ASF_SRAM_UNCORR_FAULT_ADDR ro — Last SRAM address that generated fault
0x30F28 V2A__CORE_VP__REGS_APB_ENC1_ASF_SRAM_CORR_p — Hard Slice 1 Status register for SRAM uncorrectable fault
  fields as V2A__CORE_VP__REGS_APB_ENC0_ASF_SRAM_CORR_p
0x30F2C V2A__CORE_VP__REGS_APB_ENC1_ASF_SRAM_UNCORR_p — Hard Slice 1 Status register for SRAM uncorrectable fault
  fields as V2A__CORE_VP__REGS_APB_ENC0_ASF_SRAM_UNCORR_p
0x30F30 V2A__CORE_VP__REGS_APB_ENC0_ASF_CSR_CHK_TEST_p — Hard Slice 0 Test for CSR protection expected CRC
  [15:0] ENC0_ASF_CSR_CHK_TEST rw — Each bit of the expected CRC can be corrupted separately [one bit at a time] using this register.
0x30F34 V2A__CORE_VP__REGS_APB_ENC1_ASF_CSR_CHK_TEST_p — Hard Slice 1 Test for CSR protection expected CRC
  [15:0] ENC1_ASF_CSR_CHK_TEST rw — Each bit of the expected CRC can be corrupted separately [one bit at a time] using this register.
0x30F38 V2A__CORE_VP__REGS_APB_ENC0_ASF_SELF_CHK_TEST_p — Hard Slice 0 Test for Self Check expected CRC
  [15:0] ENC0_ASF_SELF_CHK_TEST rw — Each bit of the expected CRC can be corrupted separately [one bit at a time] using this register.
0x30F3C V2A__CORE_VP__REGS_APB_ENC1_ASF_SELF_CHK_TEST_p — Hard Slice 1 Test for Self Check expected CRC
  [15:0] ENC1_ASF_SELF_CHK_TEST rw — Each bit of the expected CRC can be corrupted separately [one bit at a time] using this register.
0x30F40 V2A__CORE_VP__REGS_APB_ENC0_ASF_OUT_CHK_TEST_p — Hard Slice 0 Test for Output Checker. Each bit (one at a time) can used to corrupt various input/parameter values of the module.
  [8] END_FRAME_OUT_STUCK1_ERR rw, [7] END_LINE_OUT_STUCK1_ERR rw, [6] END_CHUNK_STUCK1_ERR rw, [5] VALID_OUT_STUCK1_ERR rw, [4] DATA_OUT_STUCK1_ERR rw, [3] VALID_STUCK0_ERR rw, [2] NVB_VALUE_ERR rw, [1] LINE_CNT_ERR rw, [0] BYTE_CNT_ERR rw
0x30F44 V2A__CORE_VP__REGS_APB_ENC1_ASF_OUT_CHK_TEST_p — Hard Slice 1 Test for Output Checker. Each bit (one at a time) can used to corrupt various input/parameter values of the module.
  fields as V2A__CORE_VP__REGS_APB_ENC0_ASF_OUT_CHK_TEST_p
